# FM33LC0XX register map
File version: 1.0
CPU: Cortex-M0 r1p0, little endian, no MPU, no FPU, 3 interrupt priority bits
Registers are 32-bit, read-write, reset 0x0 unless marked. A register's access mark holds for its fields unless they carry their own. Offsets are from the block's base; [hi:lo] are bit positions.

## OPA1 — OPA1 module information
Base 0x4001A844
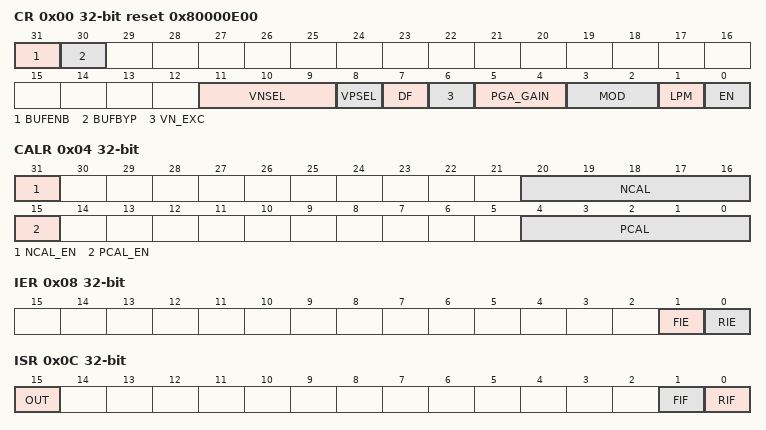
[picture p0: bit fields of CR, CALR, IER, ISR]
0x00 CR reset 0x80000E00 — OPA1 Control Register
  [31] BUFENB — BUFENB field description
  [30] BUFBYP — BUFBYP field description
  [11:9] VNSEL — VNSEL field description
  [8] VPSEL — VPSEL field description
  [7] DF — DF field description
  [6] VN_EXC — VN_EXC field description
  [5:4] PGA_GAIN — PGA_GAIN field description
  [3:2] MOD — MOD field description
  [1] LPM — LPM field description
  [0] EN — EN field description
0x04 CALR — OPA1 Calibration Register
  [31] NCAL_EN — NCAL_EN field description
  [20:16] NCAL — NCAL field description
  [15] PCAL_EN — PCAL_EN field description
  [4:0] PCAL — PCAL field description
0x08 IER — OPA1 Interrupt Enable Register
  [1] FIE — FIE field description
  [0] RIE — RIE field description
0x0C ISR access per field — OPA1 Interrupt Status Register
  [15] OUT ro — OUT field description
  [1] FIF rw — FIF field description
  [0] RIF rw — RIF field description

## OPA2 — OPA2 module information
Base 0x4001A854
Registers as OPA1 (with OPA1 read as OPA2); these are added or differ:
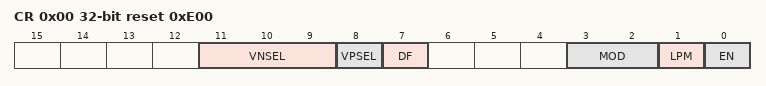
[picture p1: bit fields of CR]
0x00 CR reset 0xE00 — OPA2 Control Register
  [11:9] VNSEL — VNSEL field description
  [8] VPSEL — VPSEL field description
  [7] DF — DF field description
  [3:2] MOD — MOD field description
  [1] LPM — LPM field description
  [0] EN — EN field description

## COMP — COMP module information
Base 0x4001A870
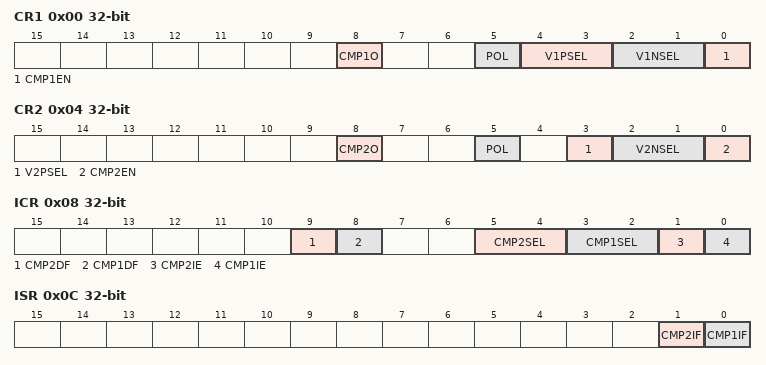
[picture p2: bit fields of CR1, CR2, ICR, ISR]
0x00 CR1 access per field — ComparatorControl Register 1
  [8] CMP1O ro — CMP1O field description
  [5] POL rw — POL field description
  [4:3] V1PSEL rw — V1PSEL field description
  [2:1] V1NSEL rw — V1NSEL field description
  [0] CMP1EN rw — CMP1EN field description
0x04 CR2 access per field — Comparator Control Register 2
  [8] CMP2O ro — CMP2O field description
  [5] POL rw — POL field description
  [3] V2PSEL rw — V2PSEL field description
  [2:1] V2NSEL rw — V2NSEL field description
  [0] CMP2EN rw — CMP2EN field description
0x08 ICR — Comparator Interrupt Config Register
  [9] CMP2DF — CMP2DF field description
  [8] CMP1DF — CMP1DF field description
  [5:4] CMP2SEL — CMP2SEL field description
  [3:2] CMP1SEL — CMP1SEL field description
  [1] CMP2IE — CMP2IE field description
  [0] CMP1IE — CMP1IE field description
0x0C ISR — Comparator Interrupt Status Register
  [1] CMP2IF — CMP2IF field description
  [0] CMP1IF — CMP1IF field description

## HDIV — HDIV module information
Base 0x40019000
0x00 END — Dividend Register
  [31:0] DIVEND — DIVEND field description
0x04 SOR — Divisor Regsiter
  [15:0] DIVSOR — DIVSOR field description
0x08 QUOT ro — Quotient Register
  [31:0] QUOT — QUOT field description
0x0C REMD ro — Reminder Register
  [15:0] REMD — REMD field description
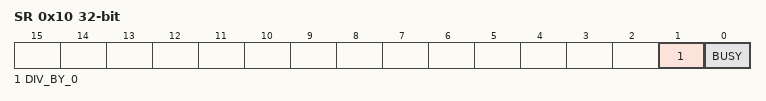
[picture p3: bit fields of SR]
0x10 SR ro — Status Register
  [1] DIV_BY_0 — DIV_BY_0 field description
  [0] BUSY — BUSY field description

## I2C — I2C module information
Base 0x40012400
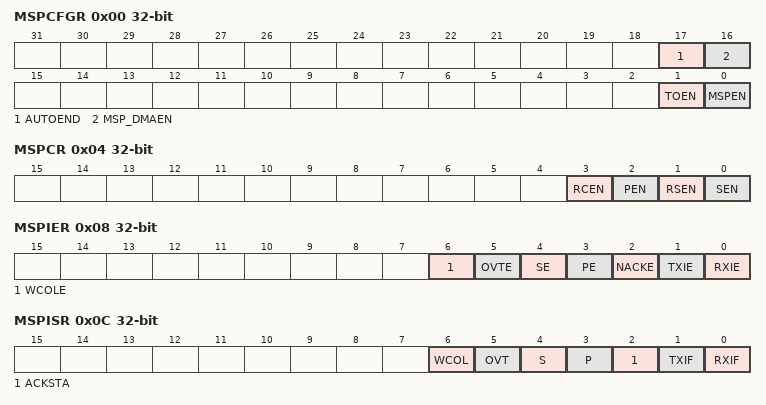
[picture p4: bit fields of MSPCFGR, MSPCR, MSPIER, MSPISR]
0x00 MSPCFGR — I2C Master Config Register
  [17] AUTOEND — AUTOEND field description
  [16] MSP_DMAEN — MSP_DMAEN field description
  [1] TOEN — TOEN field description
  [0] MSPEN — MSPEN field description
0x04 MSPCR — I2C Master Control Register
  [3] RCEN — RCEN field description
  [2] PEN — PEN field description
  [1] RSEN — RSEN field description
  [0] SEN — SEN field description
0x08 MSPIER — I2C Master Intterupt Enable Register
  [6] WCOLE — WCOLE field description
  [5] OVTE — OVTE field description
  [4] SE — SE field description
  [3] PE — PE field description
  [2] NACKE — NACKE field description
  [1] TXIE — TXIE field description
  [0] RXIE — RXIE field description
0x0C MSPISR access per field — I2C Master Interrupt Status Register
  [6] WCOL rw — WCOL field description
  [5] OVT ro — OVT field description
  [4] S ro — S field description
  [3] P ro — P field description
  [2] ACKSTA rw — ACKSTA field description
  [1] TXIF rw — TXIF field description
  [0] RXIF rw — RXIF field description
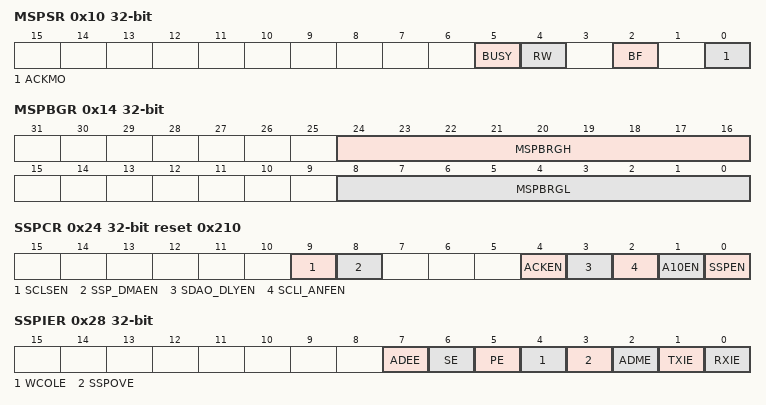
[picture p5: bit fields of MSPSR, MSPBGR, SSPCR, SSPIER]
0x10 MSPSR access per field — I2C Master Status Register
  [5] BUSY ro — BUSY field description
  [4] RW ro — RW field description
  [2] BF ro — BF field description
  [0] ACKMO rw — ACKMO field description
0x14 MSPBGR — I2C Master Baud rate Generator Register
  [24:16] MSPBRGH — MSPBRGH field description
  [8:0] MSPBRGL — MSPBRGL field description
0x18 MSPBUF — I2C Master transfer Buffer
  [7:0] MSPBUF — MSPBUF field description
0x1C MSPTCR — I2C Master Timing Control Register
  [8:0] SDAHD — SDAHD field description
0x20 MSPTOR reset 0xF00 — I2C Master Time-Out Register
  [11:0] TIMEOUT — TIMEOUT field description
0x24 SSPCR reset 0x210 — I2C Slave Control Register
  [9] SCLSEN — SCLSEN field description
  [8] SSP_DMAEN — SSP_DMAEN field description
  [4] ACKEN — ACKEN field description
  [3] SDAO_DLYEN — SDAO_DLYEN field description
  [2] SCLI_ANFEN — SCLI_ANFEN field description
  [1] A10EN — A10EN field description
  [0] SSPEN — SSPEN field description
0x28 SSPIER — I2C Slave Interrupt Enable Register
  [7] ADEE — ADEE field description
  [6] SE — SE field description
  [5] PE — PE field description
  [4] WCOLE — WCOLE field description
  [3] SSPOVE — SSPOVE field description
  [2] ADME — ADME field description
  [1] TXIE — TXIE field description
  [0] RXIE — RXIE field description
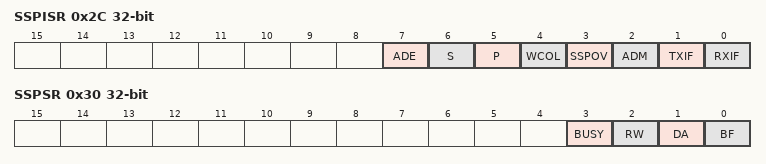
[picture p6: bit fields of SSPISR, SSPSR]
0x2C SSPISR access per field — I2C Slave Interrupt Status Register
  [7] ADE rw — ADE field description
  [6] S ro — S field description
  [5] P ro — P field description
  [4] WCOL rw — WCOL field description
  [3] SSPOV rw — SSPOV field description
  [2] ADM rw — ADM field description
  [1] TXIF rw — TXIF field description
  [0] RXIF rw — RXIF field description
0x30 SSPSR ro — I2C Slave Status Register
  [3] BUSY — BUSY field description
  [2] RW — RW field description
  [1] DA — DA field description
  [0] BF — BF field description
0x34 SSPBUF — I2C Slave transfer Buffer
  [7:0] SSPBUF — SSPBUF field description
0x38 SSPADR — I2C Slave Address Register
  [9:0] SSPADDR — SSPADDR field description
